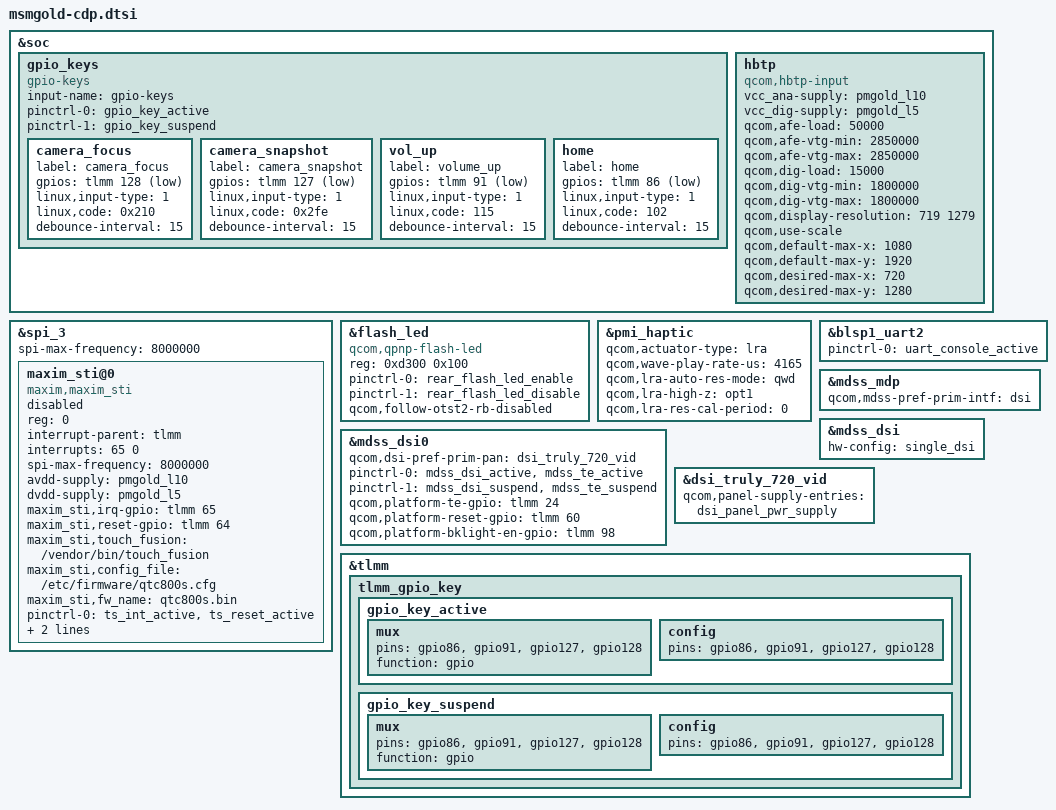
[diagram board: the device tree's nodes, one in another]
/*
 * Copyright (c) 2015-2016, The Linux Foundation. All rights reserved.
 *
 * This program is free software; you can redistribute it and/or modify
 * it under the terms of the GNU General Public License version 2 and
 * only version 2 as published by the Free Software Foundation.
 *
 * This program is distributed in the hope that it will be useful,
 * but WITHOUT ANY WARRANTY; without even the implied warranty of
 * MERCHANTABILITY or FITNESS FOR A PARTICULAR PURPOSE.  See the
 * GNU General Public License for more details.
 */

#include "msmgold-pinctrl.dtsi"
#include "msmgold-camera-sensor-cdp.dtsi"

&soc {
	gpio_keys {
		compatible = "gpio-keys";
		input-name = "gpio-keys";
		pinctrl-names = "tlmm_gpio_key_active","tlmm_gpio_key_suspend";
		pinctrl-0 = <&gpio_key_active>;
		pinctrl-1 = <&gpio_key_suspend>;

		camera_focus {
			label = "camera_focus";
			gpios = <&tlmm 128 0x1>;
			linux,input-type = <1>;
			linux,code = <0x210>;
			debounce-interval = <15>;
		};

		camera_snapshot {
			label = "camera_snapshot";
			gpios = <&tlmm 127 0x1>;
			linux,input-type = <1>;
			linux,code = <0x2fe>;
			debounce-interval = <15>;
		};

		vol_up {
			label = "volume_up";
			gpios = <&tlmm 91 0x1>;
			linux,input-type = <1>;
			linux,code = <115>;
			debounce-interval = <15>;
		};

		home {
			label = "home";
			gpios = <&tlmm 86 0x1>;
			linux,input-type = <1>;
			linux,code = <102>;
			debounce-interval = <15>;
		};
	};

	hbtp {
		compatible = "qcom,hbtp-input";
		vcc_ana-supply = <&pmgold_l10>;
		vcc_dig-supply = <&pmgold_l5>;
		qcom,afe-load = <50000>;
		qcom,afe-vtg-min = <2850000>;
		qcom,afe-vtg-max = <2850000>;
		qcom,dig-load = <15000>;
		qcom,dig-vtg-min = <1800000>;
		qcom,dig-vtg-max = <1800000>;
		qcom,display-resolution = <719 1279>;
		qcom,use-scale;
		qcom,default-max-x = <1080>;
		qcom,default-max-y = <1920>;
		qcom,desired-max-x = <720>;
		qcom,desired-max-y = <1280>;
	};
};

&spi_3 { /* BLSP1 QUP3 */
	spi-max-frequency = <8000000>;
	maxim_sti@0 {
		status = "disabled";
		compatible = "maxim,maxim_sti";
		reg = <0>;
		interrupt-parent = <&tlmm>;
		interrupts = <65 0>;
		spi-max-frequency = <8000000>;
		avdd-supply = <&pmgold_l10>;
		dvdd-supply = <&pmgold_l5>;
		maxim_sti,irq-gpio = <&tlmm 65 0x00>;
		maxim_sti,reset-gpio = <&tlmm 64 0x00>;
		maxim_sti,touch_fusion = "/vendor/bin/touch_fusion";
		maxim_sti,config_file = "/etc/firmware/qtc800s.cfg";
		maxim_sti,fw_name = "qtc800s.bin";
		pinctrl-names = "pmx_ts_active","pmx_ts_suspend",
			"pmx_ts_release";
		pinctrl-0 = <&ts_int_active &ts_reset_active>;
		pinctrl-1 = <&ts_int_suspend &ts_reset_suspend>;
		pinctrl-2 = <&ts_release>;
	};
};

&flash_led {
	compatible = "qcom,qpnp-flash-led";
	reg = <0xd300 0x100>;
	pinctrl-names = "flash_led_enable","flash_led_disable";
	pinctrl-0 = <&rear_flash_led_enable>;
	pinctrl-1 = <&rear_flash_led_disable>;
	qcom,follow-otst2-rb-disabled;
};

&pmi_haptic{
	qcom,actuator-type = "lra";
	qcom,wave-play-rate-us = <4165>;
	qcom,lra-auto-res-mode="qwd";
	qcom,lra-high-z="opt1";
	qcom,lra-res-cal-period = <0>;
};

&blsp1_uart2 {
	status = "ok";
	pinctrl-names = "default";
	pinctrl-0 = <&uart_console_active>;
};

#include "msm8937-mdss-panels.dtsi"

&mdss_mdp {
	qcom,mdss-pref-prim-intf = "dsi";
};

&mdss_dsi {
	hw-config = "single_dsi";
};

&mdss_dsi0 {
	qcom,dsi-pref-prim-pan = <&dsi_truly_720_vid>;
	pinctrl-names = "mdss_default", "mdss_sleep";
	pinctrl-0 = <&mdss_dsi_active &mdss_te_active>;
	pinctrl-1 = <&mdss_dsi_suspend &mdss_te_suspend>;

	qcom,platform-te-gpio = <&tlmm 24 0>;
	qcom,platform-reset-gpio = <&tlmm 60 0>;
	qcom,platform-bklight-en-gpio = <&tlmm 98 0>;
};

&dsi_truly_720_vid {
	qcom,panel-supply-entries = <&dsi_panel_pwr_supply>;
};

&tlmm {
	tlmm_gpio_key {
		gpio_key_active: gpio_key_active {
			mux {
				pins = "gpio86", "gpio91", "gpio127", "gpio128";
				function = "gpio";
			};

			config {
				pins = "gpio86", "gpio91", "gpio127", "gpio128";
			};
		};

		gpio_key_suspend: gpio_key_suspend {
			mux {
				pins = "gpio86", "gpio91", "gpio127", "gpio128";
				function = "gpio";
			};

			config {
				pins = "gpio86", "gpio91", "gpio127", "gpio128";
			};
		};
	};
};
